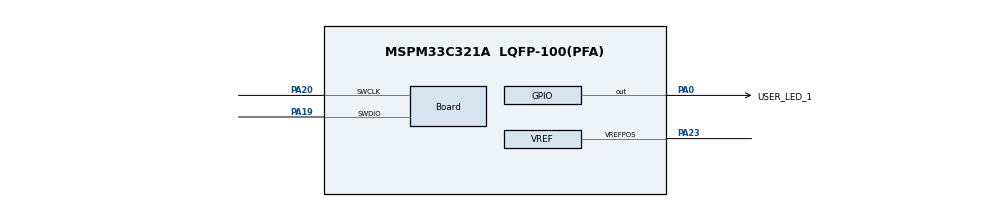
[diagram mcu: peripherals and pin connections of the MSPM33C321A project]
//@cliArgs --device "MSPM33C321A" --package "LQFP-100(PFA)" --part "Default"
//@v2CliArgs --device "MSPM33C321A" --package "LQFP-100(PFA)"
// @cliArgs --board /ti/boards/LP_MSPM33C321A --rtos nortos

/**
 * Import the modules used in this configuration.
 */
const GPIO   = scripting.addModule("/ti/driverlib/GPIO", {}, false);
const GPIO1  = GPIO.addInstance();
const HSADC  = scripting.addModule("/ti/driverlib/HSADC", {}, false);
const HSADC1 = HSADC.addInstance();
const SYSCTL = scripting.addModule("/ti/driverlib/SYSCTL");
const VREF   = scripting.addModule("/ti/driverlib/VREF");

/**
 * Write custom configuration values to the imported modules.
 */
GPIO1.$name                               = "GPIO_LEDS_1";
GPIO1.associatedPins[0].$name             = "USER_LED_1";
GPIO1.associatedPins[0].launchPadShortcut = "LED1En";
GPIO1.associatedPins[0].pin.$assign       = "PA0";

const Board                       = scripting.addModule("/ti/driverlib/Board", {}, false);
Board.peripheral.$assign          = "DEBUGSS";
Board.peripheral.swclkPin.$assign = "PA20";
Board.peripheral.swdioPin.$assign = "PA19";

HSADC1.$name              = "HSADC0";
HSADC1.enabledSOCs        = ["ADC_SOC_NUMBER0"];
HSADC1.enabledInts        = ["ADC_INT_NUMBER_1"];
HSADC1.enableInterrupt1   = true;
HSADC1.enabledSEQs        = ["ADC_SEQ_NUMBER1"];
HSADC1.seq1SampleWindow   = 16;
HSADC1.seq1Enable         = true;
HSADC1.peripheral.$assign = "ADC0";

SYSCTL.forceDefaultClkConfig = true;
SYSCTL.peripheral.$assign    = "SYSCTL";

VREF.advClockConfigEnable          = true;
VREF.advClkSrc                     = "DL_VREF_CLOCK_BUSCLK";
VREF.vrefPosPinConfig.$name        = "ti_driverlib_gpio_GPIOPinGeneric0";
VREF.peripheral.$assign            = "VREF";
VREF.peripheral.vrefPosPin.$assign = "PA23";

const ProjectConfig              = scripting.addModule("/ti/project_config/ProjectConfig", {}, false);
ProjectConfig.migrationCondition = true;
ProjectConfig.genLinker          = true;
ProjectConfig.genStartup         = true;
ProjectConfig.genOpts            = true;
ProjectConfig.genLibs            = true;
